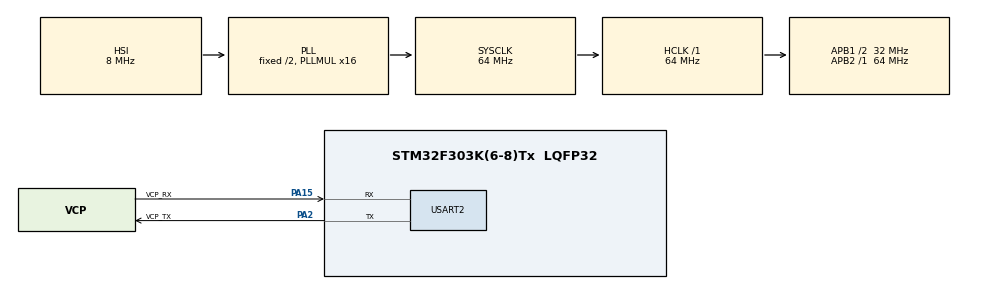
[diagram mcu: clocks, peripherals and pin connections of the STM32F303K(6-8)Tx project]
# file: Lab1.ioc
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Mcu.Family=STM32F3
Mcu.Name=STM32F303K(6-8)Tx
Mcu.Package=LQFP32
NVIC.PriorityGroup=NVIC_PRIORITYGROUP_4
PA13.GPIO_Label=SWDIO
PA13.Mode=Serial_Wire
PA13.Signal=SYS_JTMS-SWDIO
PA14.GPIO_Label=SWCLK
PA14.Mode=Serial_Wire
PA14.Signal=SYS_JTCK-SWCLK
PA15.GPIO_Label=VCP_RX
PA15.Mode=Asynchronous
PA15.Signal=USART2_RX
PA2.GPIO_Label=VCP_TX
PA2.Mode=Asynchronous
PA2.Signal=USART2_TX
PF0\ /\ OSC_IN.GPIO_Label=MCO
PF0\ /\ OSC_IN.Mode=HSE-External-Clock-Source
PF0\ /\ OSC_IN.Signal=RCC_OSC_IN
ProjectManager.HeapSize=0x200
ProjectManager.StackSize=0x400
ProjectManager.TargetToolchain=STM32CubeIDE
RCC.AHBFreq_Value=64000000
RCC.APB1CLKDivider=RCC_HCLK_DIV2
RCC.APB1Freq_Value=32000000
RCC.APB1TimFreq_Value=64000000
RCC.APB2Freq_Value=64000000
RCC.APB2TimFreq_Value=64000000
RCC.CortexFreq_Value=64000000
RCC.HCLKFreq_Value=64000000
RCC.HSE_VALUE=8000000
RCC.HSI_VALUE=8000000
RCC.PLLMUL=RCC_PLL_MUL16
RCC.SYSCLKFreq_VALUE=64000000
RCC.SYSCLKSourceVirtual=RCC_SYSCLKSOURCE_PLLCLK
USART2.VirtualMode-Asynchronous=VM_ASYNC
board=NUCLEO-F303K8

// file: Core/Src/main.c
/* USER CODE BEGIN Header */
/**
  ******************************************************************************
  * @file           : main.c
  * @brief          : Main program body
  ******************************************************************************
  * @attention
  *
  * Copyright (c) 2023 STMicroelectronics.
  * All rights reserved.
  *
  * This software is licensed under terms that can be found in the LICENSE file
  * in the root directory of this software component.
  * If no LICENSE file comes with this software, it is provided AS-IS.
  *
  ******************************************************************************
  */
/* USER CODE END Header */
#include "main.h"
#define OFF     0
#define PUSH    1
#define ON      2
#define RELEASE 3

unsigned char state;

void wait()
{
    volatile int i = 0;
    for (i = 0; i < 2000000; i++);
}

/* USER CODE BEGIN Includes */
void setup()
{
	//Question 1.

  // Enable clock for port B
  RCC->AHBENR |= 0x1<<18;

  // Config LED green = PB0
  // Output : page 237 datasheet, put "01" at index 0
  GPIOB->MODER &=  ~(0x3<<0); // 0x3 to reset and put "00"
  GPIOB->MODER |= 0x01<<0; // Put 1
  // LED green ON, put '1' at index 0
  GPIOB->ODR |= 0x1 << 0;

  //Question 2.

  // Config D6/PB1 as input + pull-up
  // PB1 input, put "00" at index 2
  // By default, yet an input !
  // Othewise
  GPIOB->MODER &= ~(0x3<<2);
  // Put pull-up, page 238 datasheet
  // put "01" at index 2
  GPIOB->PUPDR &= ~(0x3<<2); // = 0x03 to reset
  GPIOB->PUPDR |= 0x01<<2;
  // or
  //GPIOB->PUPDR &= 0xFFFFFFF7;
  //GPIOB->PUPDR |= 0x00000004;

 }
/* USER CODE END Includes */

UART_HandleTypeDef huart2;

void SystemClock_Config(void);
static void MX_GPIO_Init(void);
static void MX_USART2_UART_Init(void);

int main(void)
{
  /* USER CODE BEGIN 1 */
	setup();

  /* USER CODE END 1 */

  /* MCU Configuration--------------------------------------------------------*/

  /* Reset of all peripherals, Initializes the Flash interface and the Systick. */
  HAL_Init();

  /* Configure the system clock */
  SystemClock_Config();

  /* Initialize all configured peripherals */
  MX_GPIO_Init();
  MX_USART2_UART_Init();

  /* Infinite loop */
  /* USER CODE BEGIN WHILE */
  while (1)
  {
      switch(state)
      {
        case OFF :
          if( (GPIOB->IDR & 0x2) == 0)
          { // When we push PB1
            state = PUSH;
          }
          break;

        case PUSH :
          state = ON;
          break;

        case ON :
          if( (GPIOB->IDR & 0x2) == 0x2)
          {
            state = RELEASE;
          }
          break;

        case RELEASE :
          state = OFF;
          break;
      }

      if(state == PUSH)
      {
        GPIOB->ODR ^= 0X01;
      }

      wait();

  }
}

void SystemClock_Config(void)
{
  RCC_OscInitTypeDef RCC_OscInitStruct = {0};
  RCC_ClkInitTypeDef RCC_ClkInitStruct = {0};

  /** Initializes the RCC Oscillators according to the specified parameters
  * in the RCC_OscInitTypeDef structure.
  */
  RCC_OscInitStruct.OscillatorType = RCC_OSCILLATORTYPE_HSI;
  RCC_OscInitStruct.HSIState = RCC_HSI_ON;
  RCC_OscInitStruct.HSICalibrationValue = RCC_HSICALIBRATION_DEFAULT;
  RCC_OscInitStruct.PLL.PLLState = RCC_PLL_ON;
  RCC_OscInitStruct.PLL.PLLSource = RCC_PLLSOURCE_HSI;
  RCC_OscInitStruct.PLL.PLLMUL = RCC_PLL_MUL16;
  if (HAL_RCC_OscConfig(&RCC_OscInitStruct) != HAL_OK)
  {
    Error_Handler();
  }

  /** Initializes the CPU, AHB and APB buses clocks
  */
  RCC_ClkInitStruct.ClockType = RCC_CLOCKTYPE_HCLK|RCC_CLOCKTYPE_SYSCLK
                              |RCC_CLOCKTYPE_PCLK1|RCC_CLOCKTYPE_PCLK2;
  RCC_ClkInitStruct.SYSCLKSource = RCC_SYSCLKSOURCE_PLLCLK;
  RCC_ClkInitStruct.AHBCLKDivider = RCC_SYSCLK_DIV1;
  RCC_ClkInitStruct.APB1CLKDivider = RCC_HCLK_DIV2;
  RCC_ClkInitStruct.APB2CLKDivider = RCC_HCLK_DIV1;

  if (HAL_RCC_ClockConfig(&RCC_ClkInitStruct, FLASH_LATENCY_2) != HAL_OK)
  {
    Error_Handler();
  }
}

static void MX_USART2_UART_Init(void)
{

  huart2.Instance = USART2;
  huart2.Init.BaudRate = 38400;
  huart2.Init.WordLength = UART_WORDLENGTH_8B;
  huart2.Init.StopBits = UART_STOPBITS_1;
  huart2.Init.Parity = UART_PARITY_NONE;
  huart2.Init.Mode = UART_MODE_TX_RX;
  huart2.Init.HwFlowCtl = UART_HWCONTROL_NONE;
  huart2.Init.OverSampling = UART_OVERSAMPLING_16;
  huart2.Init.OneBitSampling = UART_ONE_BIT_SAMPLE_DISABLE;
  huart2.AdvancedInit.AdvFeatureInit = UART_ADVFEATURE_NO_INIT;
  if (HAL_UART_Init(&huart2) != HAL_OK)
  {
    Error_Handler();
  }

}

static void MX_GPIO_Init(void)
{

  /* GPIO Ports Clock Enable */
  __HAL_RCC_GPIOF_CLK_ENABLE();
  __HAL_RCC_GPIOA_CLK_ENABLE();

}

void Error_Handler(void)
{
  __disable_irq();
  while (1)
  {
  }
}
